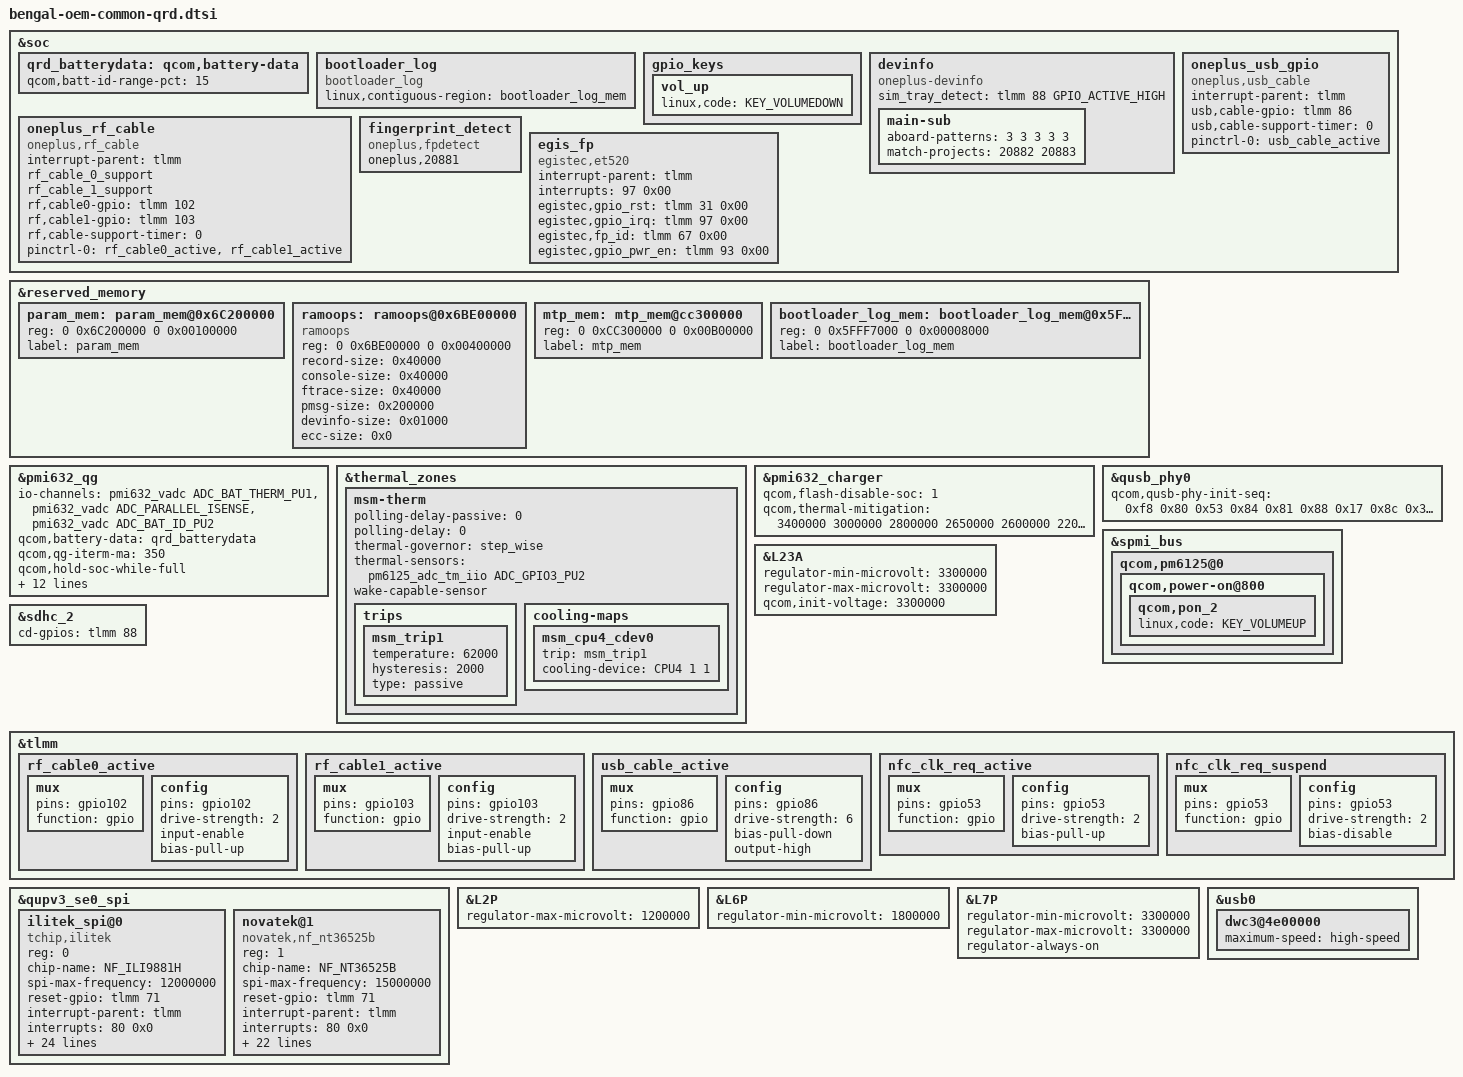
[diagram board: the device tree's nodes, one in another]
/* DTB: Platform related generic modifications */
#include "display/bengal-oem-display.dtsi"

/delete-node/ &qrd_batterydata;
&soc {
	qrd_batterydata: qcom,battery-data {
		qcom,batt-id-range-pct = <15>;
		#include "oneplus_battery_5000mah_15k_pmi632_Coslight.dtsi"
		#include "oneplus_battery_5000mah_27k_pmi632_Desay.dtsi"
	};

	bootloader_log {
		compatible = "bootloader_log";
		linux,contiguous-region = <&bootloader_log_mem>;
	};
};

&reserved_memory {
    param_mem: param_mem@0x6C200000 {
        reg = <0 0x6C200000 0 0x00100000>;
        label = "param_mem";
    };

    ramoops: ramoops@0x6BE00000 {
        compatible = "ramoops";
        reg = <0 0x6BE00000 0 0x00400000>;
        record-size =  <0x40000>; //256x1024
        console-size = <0x40000>;
        ftrace-size =  <0x40000>;
        pmsg-size=         <0x200000>;
        devinfo-size=  <0x01000>;
        ecc-size=          <0x0>;
    };

    mtp_mem: mtp_mem@cc300000 {
        reg = <0 0xCC300000 0 0x00B00000>;
        label = "mtp_mem";
    };

    bootloader_log_mem: bootloader_log_mem@0x5FFF7000 {
        reg = <0 0x5FFF7000 0 0x00008000>;
        label = "bootloader_log_mem";
    };
};

&pmi632_qg {
	io-channels = <&pmi632_vadc ADC_BAT_THERM_PU1>,
		      <&pmi632_vadc ADC_PARALLEL_ISENSE>,
		      <&pmi632_vadc ADC_BAT_ID_PU2>;

        io-channel-names = "batt-therm",
                           "parallel_isense",
                           "batt-id";

	qcom,battery-data = <&qrd_batterydata>;
	qcom,qg-iterm-ma = <350>;
	qcom,hold-soc-while-full;
	qcom,linearize-soc;
	qcom,qg-use-s7-ocv;
	qcom,tcss-enable;
	qcom,tcss-entry-soc = <90>;

	qcom,s3-entry-ibat-ua = <25000>;
	qcom,s3-exit-ibat-ua = <38000>;
	qcom,enable-qpnp-qg;
	qcom,vbatt-cutoff-mv = <3390>;
	qcom,ignore-shutdown-soc-secs = <7200>;
	qcom,shutdown-temp-diff = <200>;
	qcom,fvss-enable;
	qcom,cl-feedback-on;
};

&thermal_zones {
        msm-therm {
                polling-delay-passive = <0>;
                polling-delay = <0>;
                thermal-governor = "step_wise";
                thermal-sensors = <&pm6125_adc_tm_iio ADC_GPIO3_PU2>;
                wake-capable-sensor;
                trips {
                        msm_trip1:msm_trip1 {
                                temperature = <62000>;
                                hysteresis = <2000>;
                                type = "passive";
                        };
                };

                cooling-maps {
                        msm_cpu4_cdev0 {
                                trip = <&msm_trip1>;
                                cooling-device = <&CPU4 1 1>;
                        };
                };
        };
};

&pmi632_charger {
	qcom,flash-disable-soc = <1>;
	qcom,thermal-mitigation = <3400000 3000000
				2800000 2650000 2600000 2200000>;
};

&qusb_phy0 {
	qcom,qusb-phy-init-seq = <0xf8 0x80
				0x53 0x84
				0x81 0x88
				0x17 0x8c
				0x30 0x08
				0x79 0x0c
				0x21 0x10
				0x14 0x9c
				0x80 0x04
				0x9f 0x1c
				0x00 0x18>;
};

// switch vol+/vol-
&soc {
	gpio_keys {
		vol_up {
			linux,code = <KEY_VOLUMEDOWN>;
		};
	};
};
&spmi_bus {
	qcom,pm6125@0 {
		qcom,power-on@800 {
			qcom,pon_2 {
				linux,code = <KEY_VOLUMEUP>;
			};
		};
	};
};

&L23A {
	regulator-min-microvolt = <3300000>;
	regulator-max-microvolt = <3300000>;
	qcom,init-voltage = <3300000>;
};

&sdhc_2 {
	cd-gpios = <&tlmm 88 GPIO_ACTIVE_HIGH>;
};

&tlmm {
                
                /* zuoqiquan@BSP.CHG.Basic 2020/6/13 modify for rf-cable */
                rf_cable0_active: rf_cable0_active {
                        mux {
                                pins = "gpio102";
                                function = "gpio";
                        };
                        config {
                                pins = "gpio102";
                                drive-strength = <2>;
                                input-enable;
                                bias-pull-up;
                        };
                };
                rf_cable1_active: rf_cable1_active {
                        mux {
                                pins = "gpio103";
                                function = "gpio";
                        };
                        config {
                                pins = "gpio103";
                                drive-strength = <2>;
                                input-enable;
                                bias-pull-up;
                        };
                };
                //#endif 
                usb_cable_active: usb_cable_active {
                        mux {
                                pins = "gpio86";
                                function = "gpio";
                        };
                        config {
                                pins = "gpio86";
                                drive-strength = <6>; /* 2 MA */
                                bias-pull-down; /* bias-pull-up; */
                                output-high;
                        };
                };

                nfc_clk_req_active: nfc_clk_req_active {
                        /* active state */
                        mux {
                                /* GPIO 53: NFC CLOCK REQUEST */
                                pins = "gpio53";
                                function = "gpio";
                        };

                        config {
                                pins = "gpio53";
                                drive-strength = <2>; /* 2 MA */
                                bias-pull-up;
                        };
                };

                nfc_clk_req_suspend: nfc_clk_req_suspend {
                        /* sleep state */
                        mux {
                                /* GPIO 53: NFC CLOCK REQUEST */
                                pins = "gpio53";
                                function = "gpio";
                        };

                        config {
                                pins = "gpio53";
                                drive-strength = <2>; /* 2 MA */
                                bias-disable;
                        };
                };
};

&soc {
	/* n1 */
	devinfo {
		compatible = "oneplus-devinfo";
		sim_tray_detect = <&tlmm 88 GPIO_ACTIVE_HIGH>;
		main-sub {
			//compatible = "hw-match, main-sub";

			//aboard-gpio0 = <&tlmm 68 0x1>;  //KB
			//aboard-gpio1 = <&tlmm 101 0x1>; //MB
			aboard-patterns = <3 3 3 3 3>;

			/* main board */
			match-projects = <20882 20883>;
		};
	};

	oneplus_rf_cable {
		compatible = "oneplus,rf_cable";
		interrupt-parent = <&tlmm>;
		rf_cable_0_support;
		rf_cable_1_support;
		rf,cable0-gpio = <&tlmm 102 0>;
		rf,cable1-gpio = <&tlmm 103 0>;
		rf,cable-support-timer = <0>;
		pinctrl-names = "rf_cable_active";
		pinctrl-0 = <&rf_cable0_active &rf_cable1_active>;
	};

	oneplus_usb_gpio {
		compatible = "oneplus,usb_cable";
		interrupt-parent = <&tlmm>;
		usb,cable-gpio = <&tlmm 86 0>;
		usb,cable-support-timer = <0>;
		pinctrl-names = "usb_cable_active";
		pinctrl-0 = <&usb_cable_active>;
	};
};

&qupv3_se0_spi {

	status = "ok";
	ilitek_spi@0 {
		compatible = "tchip,ilitek";
		reg = <0>;
		chip-name = "NF_ILI9881H";
		status = "ok";

		spi-max-frequency = <12000000>;    //4800000,9600000,15000000,19200000
		reset-gpio = <&tlmm 71 0x00>;
		interrupt-parent = <&tlmm>;
		interrupts = <80 0x0>;
		irq-gpio = <&tlmm 80 0x2002>;

		touchpanel,max-num-support = <10>;
		touchpanel,tx-rx-num = <18 32>;
		touchpanel,panel-coords = <720 1600>;
		touchpanel,display-coords = <720 1600>;
		touchpanel,touchmajor-limit = <0 54>;

		pinctrl-names = "default", "suspend";
		pinctrl-0 = <&ts_int_active &ts_reset_active>;
		pinctrl-1 = <&ts_int_suspend &ts_reset_suspend>;

		incell_screen;
		fw_edge_limit_support;
		black_gesture_support;
		charger_pump_support;
		headset_pump_support;
		//esd_handle_support;
		//spurious_fingerprint_support;
		//lcd_trigger_fp_check;
		black_gesture_test_support;
		noflash_support;
		smart_gesture_support;
		pressure_report_support;
		fw_update_app_support;
		game_switch_support;
		drlimit_remove_support;
		lcd_trigger_load_tp_fw_support;
		suspend_gesture_cfg;
		fw_update_in_probe_with_headfile;

		touchpanel,button-type = <4>;
	};
	novatek@1 {
		compatible = "novatek,nf_nt36525b";
		reg = <1>;
		chip-name = "NF_NT36525B";
		status = "ok";

		spi-max-frequency = <15000000>;	//4800000,9600000,15000000,19200000
		reset-gpio = <&tlmm 71 0x00>;
		interrupt-parent = <&tlmm>;
		interrupts = <80 0x0>;
		irq-gpio = <&tlmm 80 0x2002>;
		lcd-reset-gpio = <&tlmm 82 0x00>;

		touchpanel,max-num-support = <10>;
		touchpanel,tx-rx-num = <18 32>;
		touchpanel,panel-coords = <720 1600>;
		touchpanel,display-coords = <720 1600>;
		touchpanel,touchmajor-limit = <0 54>;

		pinctrl-names = "default", "suspend";
		pinctrl-0 = <&ts_int_active &ts_reset_active>;
		pinctrl-1 = <&ts_int_suspend &ts_reset_suspend>;

		incell_screen;
		fw_edge_limit_support;
		black_gesture_support;
		charger_pump_support;
		headset_pump_support;
		//esd_handle_support;
		//spurious_fingerprint_support;
		//lcd_trigger_fp_check;
		black_gesture_test_support;
		noflash_support;
		smart_gesture_support;
		pressure_report_support;
		//fw_update_app_support;
		game_switch_support;
		drlimit_remove_support;
		lcd_trigger_load_tp_fw_support;
		//fw_update_in_probe_with_headfile;

		touchpanel,button-type = <4>;
	};
};

&soc {
	oneplus_usb_gpio {
		compatible = "oneplus,usb_cable";
		interrupt-parent = <&tlmm>;
		usb,cable-gpio = <&tlmm 86 0>;
		usb,cable-support-timer = <0>;
		pinctrl-names = "usb_cable_active";
		pinctrl-0 = <&usb_cable_active>;
	};

	fingerprint_detect:fingerprint_detect {
		oneplus,20881;
		compatible = "oneplus,fpdetect";
		//fp-gpio-id0 = <&tlmm 55 0>;
		//fp-gpio-id1 = <&tlmm 53 0>;
		//pinctrl-names = "fp_id_init";
		//pinctrl-0 = <&fp_id_init>;
	};
	egis_fp{
		status = "okay";
		compatible = "egistec,et520";

		interrupt-parent = <&tlmm>;
		interrupts = <97 0x00>;
		egistec,gpio_rst = <&tlmm 31 0x00>;
		egistec,gpio_irq = <&tlmm 97 0x00>;
		egistec,fp_id = <&tlmm 67 0x00>;
		egistec,gpio_pwr_en = <&tlmm 93 0x00>;
	};
};

/* add for camera bring up */
&L2P {
	regulator-max-microvolt = <1200000>;
};

&L6P {
	regulator-min-microvolt = <1800000>;
};
&L7P {
	regulator-min-microvolt = <3300000>;
	regulator-max-microvolt = <3300000>;
	regulator-always-on;
};
&usb0 {
	dwc3@4e00000 {
		 maximum-speed = "high-speed";
	};
};

#include "audio/bengal-oem-audio-overlay.dtsi"
#include "oneplus-charge.dtsi"
